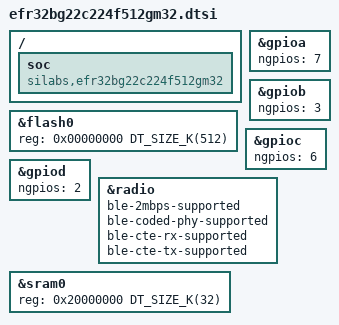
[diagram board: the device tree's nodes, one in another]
/*
 * Copyright (c) 2021 Sateesh Kotapati
 * Copyright (c) 2025 Silicon Laboratories Inc.
 *
 * SPDX-License-Identifier: Apache-2.0
 */

#include <mem.h>
#include <silabs/xg22/efr32bg22.dtsi>

/ {
	soc {
		compatible = "silabs,efr32bg22c224f512gm32", "silabs,efr32bg22", "silabs,xg22",
			     "silabs,efr32", "simple-bus";
	};
};

&flash0 {
	reg = <0x00000000 DT_SIZE_K(512)>;
};

&gpioa {
	ngpios = <7>;
};

&gpiob {
	ngpios = <3>;
};

&gpioc {
	ngpios = <6>;
};

&gpiod {
	ngpios = <2>;
};

&radio {
	ble-2mbps-supported;
	ble-coded-phy-supported;
	ble-cte-rx-supported;
	ble-cte-tx-supported;
};

&sram0 {
	reg = <0x20000000 DT_SIZE_K(32)>;
};
